# I2C register map
Vendor: Texas Instruments
Peripheral module from a debugger description file (folder CC27xxx10).
Registers are 32-bit, access per field, reset 0x0 unless marked. A register's access mark holds for its fields unless they carry their own. Offsets are as the file gives them; lines under a group give offsets from that group; [hi:lo] are bit positions; {n}, {i} and the like mark numbered series; 'fields as' and 'values as' point back to an identical list; <NAME> marks a mode.

## I2C — I2C IP module with peripheral and controller capabilities
0x00 TOAR — Target Own Address This register consists of seven address bits that identify this I2C device on the I2C bus.
  [6:0] OAR rw — Target own address. This field specifies bits a6 through a0 of the target address.
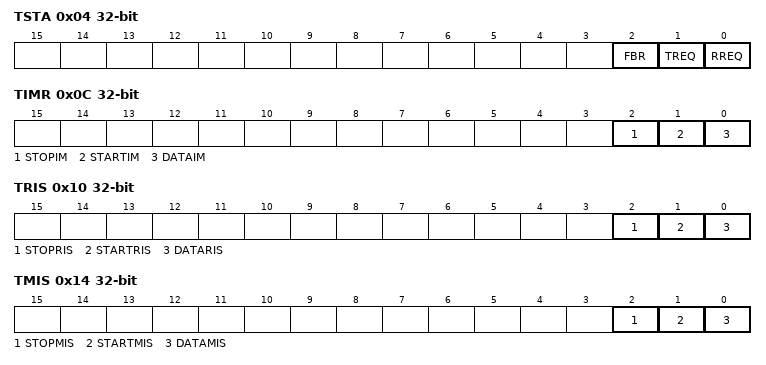
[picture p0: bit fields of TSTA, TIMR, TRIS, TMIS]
0x04 TSTA ro — Target status This register functions as a status register of the target.
  [2] FBR — First byte received. This bit is only applicable when the TSTA.RREQ bit is set and is automatically cleared when data has been read from the TDR register. Note: This bit is not used for target transmit operations.
    1=SET (The first byte following the target's own address has been received.); 0=CLR (The first byte following the target's own address has not been received)
  [1] TREQ — This field reflects the transmit request status
    1=SET (The I2C has been addressed as a target transmitter and is using clock stretching to delay the controller until data has been written to the TDR register); 0=CLR (No outstanding transmit request)
  [0] RREQ — This field reflects the receive request status.
    1=SET (The target has outstanding receive data from the external controller and is using clock stretching to delay the controller until data has been read from the TDR register); 0=CLR (No outstanding receive data)
0x04 TCTL — Target control This registers functions as a target control register
  [0] DA wo — This field sets the device active control
    1=EN (Enable the target operation); 0=DIS (Disable the target operation)
0x08 TDR — Target data register This register contains the data to be transmitted when in the target transmit state, and the data received when in the target receive state.
  [7:0] DATA rw — Data for transfer. This field contains the data for transfer during a target receive or a transmit operation. When written, the register data is used as transmit data. When read, this register returns the last data received. Data is stored until next update, either by a system write to the controller for transmit or by an external controller to the target for receive.
0x0C TIMR — Target interrupt mask This register controls whether a raw interrupt is promoted to a controller interrupt
  [all] fields
    1=EN (Enable interrupt mask); 0=DIS (Disable interrupt mask)
  [2] STOPIM rw — Stop condition interrupt mask
  [1] STARTIM rw — Start condition interrupt mask
  [0] DATAIM rw — Data interrupt mask
0x10 TRIS ro — Target raw interrupt status This register shows the unmasked interrupt status.
  [all] fields
    1=SET (Interrupt occured); 0=CLR (Interrupt did not occur)
  [2] STOPRIS — Stop condition raw interrupt status This bit is cleared by writing a 1 to TICR.STOPIC.
  [1] STARTRIS — Start condition raw interrupt status This bit is cleared by writing a 1 to TICR.STARTIC.
  [0] DATARIS — Data raw interrupt status This bit is cleared by writing a 1 to TICR.DATAIC.
0x14 TMIS ro — Target Masked Interrupt Status This register shows which interrupt is active (based on result from TRIS and TIMR registers).
  [2] STOPMIS — Stop condition masked interrupt status This bit is cleared by writing a 1 to TICR.STOPIC.
    1=SET (Masked interrupt occured); 0=CLR (Masked interrupt did not occur)
  [1] STARTMIS — Start condition masked interrupt status This bit is cleared by writing a 1 to TICR.STARTIC.
    1=SET (Masked interrput occured); 0=CLR (Masked interrupt did not occur)
  [0] DATAMIS — Start condition masked interrupt status This bit is cleared by writing a 1 to TICR.DATAIC.
    values as STOPMIS
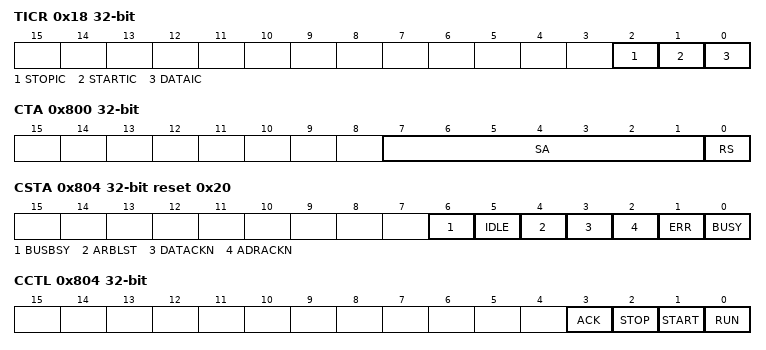
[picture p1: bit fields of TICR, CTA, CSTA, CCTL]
0x18 TICR — Target Interrupt Clear This register clears the raw interrupt TRIS
  [2] STOPIC wo — Stop condition interrupt clear
    1=EN (Clear interrupt Writing 1 to this bit clears TRIS.STOPRIS and TMIS.STOPMIS); 0=DIS (No effect)
  [1] STARTIC wo — Start condition interrupt clear
    1=EN (Clear interrupt Writing 1 to this bit clears TRIS.STARTRIS and TMIS.STARTMIS); 0=DIS (No effect)
  [0] DATAIC wo — Data interrupt clear
    1=EN (Clear interrupt Writing 1 to this bit clears TRIS.DATARIS and TMIS.DATAMIS); 0=DIS (No effect)
0x800 CTA — Controller target address This register contains seven address bits of the target to be accessed by the controller (a6-a0), and an CTA.RS bit determining if the next operation is a receive or transmit
  [7:1] SA rw — Controller target address Defines which target is addressed for the transaction in controller mode
  [0] RS rw — Receive or Send This bit-field specifies the next operation with addressed target CTA.SA.
    1=EN (Receive data from target); 0=DIS (Transmit/send data to target)
0x804 CSTA ro reset 0x20 — Controller status This register functions as a controller status register
  [6] BUSBSY — Bus busy Note:The bit changes based on the CCTRL.START and CCTRL.STOP conditions.
    1=SET (The bus is busy.); 0=CLR (The bus is idle.)
  [5] IDLE — This field specifies whether I2C is idle or not
    1=SET (The controller is idle.); 0=CLR (The controller is not idle.)
  [4] ARBLST — The filed specifies the arbitration status
    1=SET (The controller lost arbitration.); 0=CLR (The controller won arbitration.)
  [3] DATACKN — This field contains Data acknowledge status
    1=SET (The transmitted data was not acknowledged); 0=CLR (The transmitted data was acknowledged)
  [2] ADRACKN — This field reflects the address acknowledge status
    1=SET (The transmitted address was not acknowledged); 0=CLR (The transmitted address was acknowledged)
  [1] ERR — This field reflects the error status
    1=SET (An error occurred with the last operation); 0=CLR (No error was detected on the last operation)
  [0] BUSY — This field reflects the I2C busy status Note: The I2C controller requires four CLKSVT clock cycles to assert the BUSY status after I2C controller operation has been initiated through a write into CCTL register. Hence after programming CCTL register, application is requested to wait for four CLKSVT clock cycles before issuing a controller status inquiry through a read from CSTA register. Any prior inquiry would result in wrong status being reported.
    1=SET (The controller is busy); 0=CLR (The controller is idle)
0x804 CCTL — Controller control This register functions as a controller control register
  [3] ACK wo — This field is to enable the data acknowledge. Note:This bit-field must be cleared when the I2C bus controller requires no further data to be transmitted from the target transmitter.
    1=EN (The received data byte is acknowledged automatically by the controller); 0=DIS (The received data byte is not acknowledged automatically by the controller)
  [2] STOP wo — This field is to set stop condition . Note: This bit-field determines if the cycle stops at the end of the data cycle or continues on to a repeated start condition.
    1=EN (The controller generates the stop condition); 0=DIS (The controller does not generate the stop condition)
  [1] START wo — This field is to set start or repeated start condition.
    1=EN (The controller generates the start condition.); 0=DIS (The controller does not generate the start condition)
  [0] RUN wo — This field is to set the controller enable.
    1=EN (The controller is enabled to transmit or receive data); 0=DIS (The controller is disabled.)
0x808 CDR — Controller data This register contains the data to be transmitted when in the controller transmit state and the data received when in the controller receive state.
  [7:0] DATA rw — When Read: Last RX Data is returned When Written: Data is transferred during TX transaction
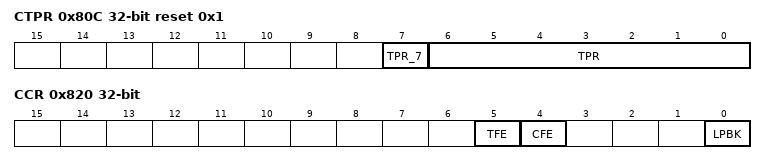
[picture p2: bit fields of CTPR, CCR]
0x80C CTPR reset 0x1 — Controller timer period This register specifies the period of the SCL clock.
  [7] TPR_7 rw — Must be set to 0 to set CTPR.TPR. If set to 1, a write to CTPR.TPR will be ignored.
  [6:0] TPR rw — SCL clock period This field specifies the period of the SCL clock. SCL_PRD = 2*(1+TPR)*(SCL_LP + SCL_HP)*CLK_PRD, where: SCL_PRD is the SCL line period (I2C clock). TPR is the timer period register value (range of 1 to 127) SCL_LP is the SCL low period (fixed at 6). SCL_HP is the SCL high period (fixed at 4). CLK_PRD is the CLKSVT period in ns.
0x810 CIMR — Controller interrupt mask This register controls whether a raw interrupt is promoted to a controller interrupt.
  [0] IM rw — Interrupt mask
    1=EN (Enable interrupt mask); 0=DIS (Disable interrupt mask)
0x814 CRIS ro — Controller raw interrupt status This register shows the unmasked interrupt status.
  [0] RIS — Raw interrupt status This bit is cleared by writing 1 to CICR.IC bit.
    1=SET (Interrupt occured); 0=CLR (Interrupt did not occur)
0x818 CMIS ro — Controller masked interrupt status This register shows which interrupt is active (based on result from CRIS and CIMR registers).
  [0] MIS — Masked interrupt status This bit is cleared by writing 1 to CICR.IC bit.
    values as TMIS.STOPMIS
0x81C CICR — Controller interrupt clear This register clears the raw and masked interrupt.
  [0] IC wo — Interrupt clear
    1=EN (Clear Interrupt Writing 1 to this bit clears CRIS.RIS and CMIS.MIS.); 0=DIS (No effect)
0x820 CCR — Controller Configuration This register configures the mode (Controller or Target) and sets the interface for test mode loopback.
  [5] TFE rw — I2C target function enable
    1=EN (Target mode enabled); 0=DIS (Target mode disabled)
  [4] CFE rw — I2C controller function enable
    1=EN (Controller mode enabled); 0=DIS (Controller mode disabled)
  [0] LPBK rw — I2C loopback
    1=EN (Test mode (Loopback operation) enabled); 0=DIS (Test mode (Loopback operation) disabled)
